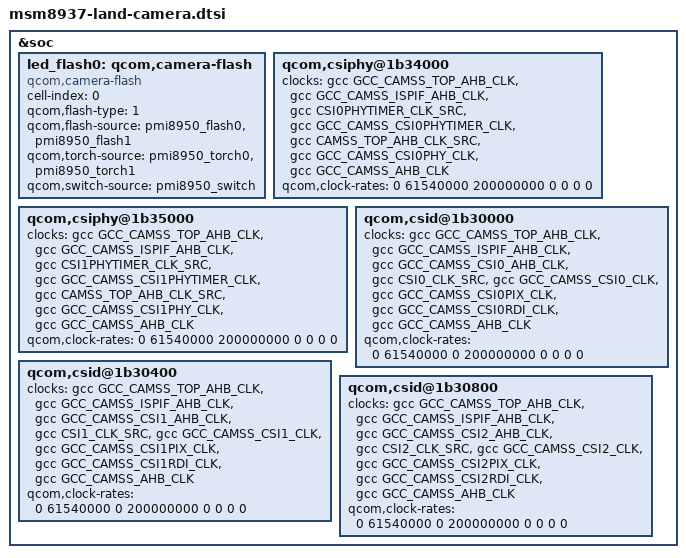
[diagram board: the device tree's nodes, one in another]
/*
 * Copyright (c) 2015-2017, The Linux Foundation. All rights reserved.
 *
 * This program is free software; you can redistribute it and/or modify
 * it under the terms of the GNU General Public License version 2 and
 * only version 2 as published by the Free Software Foundation.
 *
 * This program is distributed in the hope that it will be useful,
 * but WITHOUT ANY WARRANTY; without even the implied warranty of
 * MERCHANTABILITY or FITNESS FOR A PARTICULAR PURPOSE.  See the
 * GNU General Public License for more details.
 */

#include "msm8937-camera-sensor-land.dtsi"

&soc {
	led_flash0: qcom,camera-flash {
		cell-index = <0>;
		compatible = "qcom,camera-flash";
		qcom,flash-type = <1>;
		qcom,flash-source = <&pmi8950_flash0 &pmi8950_flash1>;
		qcom,torch-source = <&pmi8950_torch0 &pmi8950_torch1>;
		qcom,switch-source = <&pmi8950_switch>;
	};

	qcom,csiphy@1b34000 {
		clocks = <&gcc GCC_CAMSS_TOP_AHB_CLK>,
			<&gcc GCC_CAMSS_ISPIF_AHB_CLK>,
			<&gcc CSI0PHYTIMER_CLK_SRC>,
			<&gcc GCC_CAMSS_CSI0PHYTIMER_CLK>,
			<&gcc CAMSS_TOP_AHB_CLK_SRC>,
			<&gcc GCC_CAMSS_CSI0PHY_CLK>,
			<&gcc GCC_CAMSS_AHB_CLK>;
		clock-names = "camss_top_ahb_clk", "ispif_ahb_clk",
			"csiphy_timer_src_clk", "csiphy_timer_clk",
			"camss_ahb_src", "csi_phy_clk",
			"camss_ahb_clk";
		qcom,clock-rates = <0 61540000 200000000 0 0 0 0>;
	};

	qcom,csiphy@1b35000 {
		clocks = <&gcc GCC_CAMSS_TOP_AHB_CLK>,
			<&gcc GCC_CAMSS_ISPIF_AHB_CLK>,
			<&gcc CSI1PHYTIMER_CLK_SRC>,
			<&gcc GCC_CAMSS_CSI1PHYTIMER_CLK>,
			<&gcc CAMSS_TOP_AHB_CLK_SRC>,
			<&gcc GCC_CAMSS_CSI1PHY_CLK>,
			<&gcc GCC_CAMSS_AHB_CLK>;
		clock-names = "camss_top_ahb_clk", "ispif_ahb_clk",
			"csiphy_timer_src_clk", "csiphy_timer_clk",
			"camss_ahb_src", "csi_phy_clk",
			"camss_ahb_clk";
		qcom,clock-rates = <0 61540000 200000000 0 0 0 0>;
	};

	qcom,csid@1b30000 {
		clocks = <&gcc GCC_CAMSS_TOP_AHB_CLK>,
			<&gcc GCC_CAMSS_ISPIF_AHB_CLK>,
			<&gcc GCC_CAMSS_CSI0_AHB_CLK>,
			<&gcc CSI0_CLK_SRC>,
			<&gcc GCC_CAMSS_CSI0_CLK>,
			<&gcc GCC_CAMSS_CSI0PIX_CLK>,
			<&gcc GCC_CAMSS_CSI0RDI_CLK>,
			<&gcc GCC_CAMSS_AHB_CLK>;
		clock-names = "camss_top_ahb_clk",
			"ispif_ahb_clk", "csi_ahb_clk", "csi_src_clk",
			"csi_clk",  "csi_pix_clk",
			"csi_rdi_clk", "camss_ahb_clk";
		qcom,clock-rates = <0 61540000 0 200000000 0 0 0 0>;
	};

	qcom,csid@1b30400 {
		clocks = <&gcc GCC_CAMSS_TOP_AHB_CLK>,
			<&gcc GCC_CAMSS_ISPIF_AHB_CLK>,
			<&gcc GCC_CAMSS_CSI1_AHB_CLK>,
			<&gcc CSI1_CLK_SRC>,
			<&gcc GCC_CAMSS_CSI1_CLK>,
			<&gcc GCC_CAMSS_CSI1PIX_CLK>,
			<&gcc GCC_CAMSS_CSI1RDI_CLK>,
			<&gcc GCC_CAMSS_AHB_CLK>;
		clock-names = "camss_top_ahb_clk",
			"ispif_ahb_clk", "csi_ahb_clk", "csi_src_clk",
			"csi_clk", "csi_pix_clk",
			"csi_rdi_clk", "camss_ahb_clk";
		qcom,clock-rates = <0 61540000 0 200000000 0 0 0 0>;
	};

	qcom,csid@1b30800 {
		clocks = <&gcc GCC_CAMSS_TOP_AHB_CLK>,
			<&gcc GCC_CAMSS_ISPIF_AHB_CLK>,
			<&gcc GCC_CAMSS_CSI2_AHB_CLK>,
			<&gcc CSI2_CLK_SRC>,
			<&gcc GCC_CAMSS_CSI2_CLK>,
			<&gcc GCC_CAMSS_CSI2PIX_CLK>,
			<&gcc GCC_CAMSS_CSI2RDI_CLK>,
			<&gcc GCC_CAMSS_AHB_CLK>;
		clock-names = "camss_top_ahb_clk",
			"ispif_ahb_clk", "csi_ahb_clk", "csi_src_clk",
			"csi_clk", "csi_pix_clk",
			"csi_rdi_clk", "camss_ahb_clk";
		qcom,clock-rates = <0 61540000 0 200000000 0 0 0 0>;
	};
};
